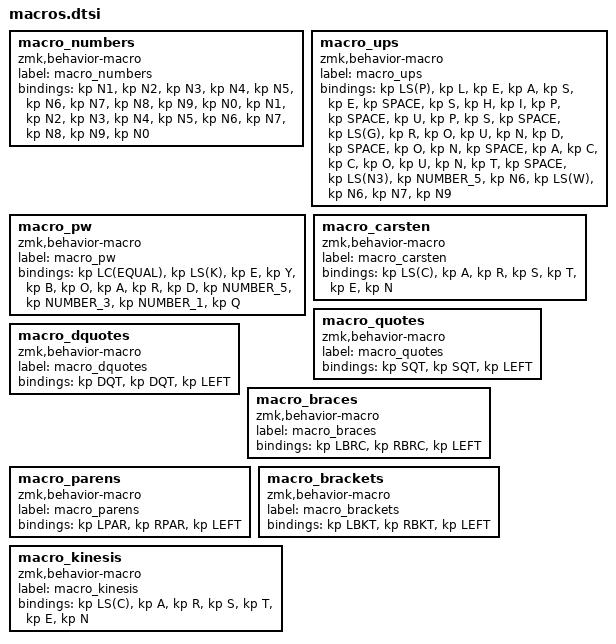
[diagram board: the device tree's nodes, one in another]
macro_numbers: macro_numbers{
compatible = "zmk,behavior-macro";
label = "macro_numbers";
#binding-cells = <0>;
bindings = <&kp N1>, <&kp N2>, <&kp N3>, <&kp N4>, <&kp N5>, <&kp N6>, <&kp N7>, <&kp N8>, <&kp N9>, <&kp N0>, <&kp N1>, <&kp N2>, <&kp N3>, <&kp N4>, <&kp N5>, <&kp N6>, <&kp N7>, <&kp N8>, <&kp N9>, <&kp N0>;
};
macro_ups: macro_ups{
compatible = "zmk,behavior-macro";
label = "macro_ups";
#binding-cells = <0>;
bindings = <&kp LS(P)>, <&kp L>, <&kp E>, <&kp A>, <&kp S>, <&kp E>, <&kp SPACE>, <&kp S>, <&kp H>, <&kp I>, <&kp P>, <&kp SPACE>, <&kp U>, <&kp P>, <&kp S>, <&kp SPACE>, <&kp LS(G)>, <&kp R>, <&kp O>, <&kp U>, <&kp N>, <&kp D>, <&kp SPACE>, <&kp O>, <&kp N>, <&kp SPACE>, <&kp A>, <&kp C>, <&kp C>, <&kp O>, <&kp U>, <&kp N>, <&kp T>, <&kp SPACE>, <&kp LS(N3)>, <&kp NUMBER_5>, <&kp N6>, <&kp LS(W)>, <&kp N6>, <&kp N7>, <&kp N9>;
};
macro_pw: macro_pw{
compatible = "zmk,behavior-macro";
label = "macro_pw";
#binding-cells = <0>;
bindings = <&kp LC(EQUAL)>, <&kp LS(K)>, <&kp E>, <&kp Y>, <&kp B>, <&kp O>, <&kp A>, <&kp R>, <&kp D>, <&kp NUMBER_5>, <&kp NUMBER_3>, <&kp NUMBER_1>, <&kp Q>;
};
macro_carsten: macro_carsten{
compatible = "zmk,behavior-macro";
label = "macro_carsten";
#binding-cells = <0>;
bindings = <&kp LS(C)>, <&kp A>, <&kp R>, <&kp S>, <&kp T>, <&kp E>, <&kp N>;
};
macro_quotes: macro_quotes{
compatible = "zmk,behavior-macro";
label = "macro_quotes";
#binding-cells = <0>;
bindings = <&kp SQT>, <&kp SQT>, <&kp LEFT>;
};
macro_dquotes: macro_dquotes{
compatible = "zmk,behavior-macro";
label = "macro_dquotes";
#binding-cells = <0>;
bindings = <&kp DQT>, <&kp DQT>, <&kp LEFT>;
};
macro_braces: macro_braces{
compatible = "zmk,behavior-macro";
label = "macro_braces";
#binding-cells = <0>;
bindings = <&kp LBRC>, <&kp RBRC>, <&kp LEFT>;
};
macro_parens: macro_parens{
compatible = "zmk,behavior-macro";
label = "macro_parens";
#binding-cells = <0>;
bindings = <&kp LPAR>, <&kp RPAR>, <&kp LEFT>;
};
macro_brackets: macro_brackets{
compatible = "zmk,behavior-macro";
label = "macro_brackets";
#binding-cells = <0>;
bindings = <&kp LBKT>, <&kp RBKT>, <&kp LEFT>;
};
macro_kinesis: macro_kinesis{
compatible = "zmk,behavior-macro";
label = "macro_kinesis";
#binding-cells = <0>;
bindings = <&kp LS(C)>, <&kp A>, <&kp R>, <&kp S>, <&kp T>, <&kp E>, <&kp N>;
};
